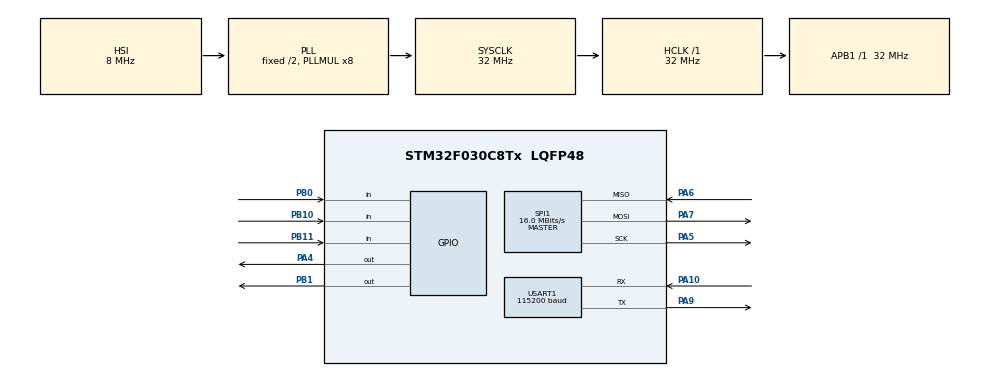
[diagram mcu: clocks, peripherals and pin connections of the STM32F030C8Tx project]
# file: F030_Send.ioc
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Mcu.Family=STM32F0
Mcu.Name=STM32F030C8Tx
Mcu.Package=LQFP48
NVIC.USART1_IRQn=true\:2\:0\:true\:false\:true\:true
PA10.Mode=Asynchronous
PA10.Signal=USART1_RX
PA13.Mode=Serial_Wire
PA13.Signal=SYS_SWDIO
PA14.Mode=Serial_Wire
PA14.Signal=SYS_SWCLK
PA4.Signal=GPIO_Output
PA5.Mode=Full_Duplex_Master
PA5.Signal=SPI1_SCK
PA6.Mode=Full_Duplex_Master
PA6.Signal=SPI1_MISO
PA7.Mode=Full_Duplex_Master
PA7.Signal=SPI1_MOSI
PA9.Mode=Asynchronous
PA9.Signal=USART1_TX
PB0.Signal=GPIO_Input
PB1.Signal=GPIO_Output
PB10.Signal=GPIO_Input
PB11.Signal=GPIO_Input
PF0-OSC_IN.Mode=HSE-External-Oscillator
PF0-OSC_IN.Signal=RCC_OSC_IN
PF1-OSC_OUT.Mode=HSE-External-Oscillator
PF1-OSC_OUT.Signal=RCC_OSC_OUT
ProjectManager.HeapSize=0x200
ProjectManager.StackSize=0x400
ProjectManager.TargetToolchain=MDK-ARM V5
RCC.AHBFreq_Value=32000000
RCC.APB1Freq_Value=32000000
RCC.APB1TimFreq_Value=32000000
RCC.HCLKFreq_Value=32000000
RCC.PLLMUL=RCC_PLL_MUL8
RCC.SYSCLKFreq_VALUE=32000000
RCC.SYSCLKSource=RCC_SYSCLKSOURCE_PLLCLK
RTC.Alarm-Alarm\ A=RTC_ALARM_A
SPI1.CalculateBaudRate=16.0 MBits/s
SPI1.DataSize=SPI_DATASIZE_8BIT
SPI1.Direction=SPI_DIRECTION_2LINES
SPI1.Mode=SPI_MODE_MASTER
SPI1.NSSPMode=SPI_NSS_PULSE_DISABLE
SPI1.VirtualType=VM_MASTER
USART1.BaudRate=115200
USART1.VirtualMode-Asynchronous=VM_ASYNC
VP_RTC_VS_RTC_Activate.Mode=RTC_Enabled
VP_RTC_VS_RTC_Alarm_A_Intern.Mode=Alarm A
VP_RTC_VS_RTC_Calendar.Mode=RTC_Calendar
board=custom

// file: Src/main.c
/* USER CODE BEGIN Header */
/**
  ******************************************************************************
  * @file           : main.c
  * @brief          : Main program body
  ******************************************************************************
  ** This notice applies to any and all portions of this file
  * that are not between comment pairs USER CODE BEGIN and
  * USER CODE END. Other portions of this file, whether
  * inserted by the user or by software development tools
  * are owned by their respective copyright owners.
  *
  * COPYRIGHT(c) 2019 STMicroelectronics
  *
  * Redistribution and use in source and binary forms, with or without modification,
  * are permitted provided that the following conditions are met:
  *   1. Redistributions of source code must retain the above copyright notice,
  *      this list of conditions and the following disclaimer.
  *   2. Redistributions in binary form must reproduce the above copyright notice,
  *      this list of conditions and the following disclaimer in the documentation
  *      and/or other materials provided with the distribution.
  *   3. Neither the name of STMicroelectronics nor the names of its contributors
  *      may be used to endorse or promote products derived from this software
  *      without specific prior written permission.
  *
  * THIS SOFTWARE IS PROVIDED BY THE COPYRIGHT HOLDERS AND CONTRIBUTORS "AS IS"
  * AND ANY EXPRESS OR IMPLIED WARRANTIES, INCLUDING, BUT NOT LIMITED TO, THE
  * IMPLIED WARRANTIES OF MERCHANTABILITY AND FITNESS FOR A PARTICULAR PURPOSE ARE
  * DISCLAIMED. IN NO EVENT SHALL THE COPYRIGHT HOLDER OR CONTRIBUTORS BE LIABLE
  * FOR ANY DIRECT, INDIRECT, INCIDENTAL, SPECIAL, EXEMPLARY, OR CONSEQUENTIAL
  * DAMAGES (INCLUDING, BUT NOT LIMITED TO, PROCUREMENT OF SUBSTITUTE GOODS OR
  * SERVICES; LOSS OF USE, DATA, OR PROFITS; OR BUSINESS INTERRUPTION) HOWEVER
  * CAUSED AND ON ANY THEORY OF LIABILITY, WHETHER IN CONTRACT, STRICT LIABILITY,
  * OR TORT (INCLUDING NEGLIGENCE OR OTHERWISE) ARISING IN ANY WAY OUT OF THE USE
  * OF THIS SOFTWARE, EVEN IF ADVISED OF THE POSSIBILITY OF SUCH DAMAGE.
  *
  ******************************************************************************
  */
/* USER CODE END Header */

#include "main.h"
#include "stm32f0xx_hal.h"
#include "function.h"
#include "SX127x.h"
#include "string.h"
#include "stm32f0xx_it.h"

RTC_HandleTypeDef hrtc;

SPI_HandleTypeDef hspi1;

UART_HandleTypeDef huart1;
 int8_t  USART_RX_BUF[50]; //接收缓冲,最大USART_REC_LEN个字节.末字节为换行符
 int16_t USART_RX_STA;         		//接收状态标记
 int8_t aRxBuffer[1];//HAL库USART接收Buffer

void SystemClock_Config(void);
static void MX_GPIO_Init(void);
static void MX_RTC_Init(void);
static void MX_SPI1_Init(void);
static void MX_USART1_UART_Init(void);

int main(void)
{

  /* MCU Configuration--------------------------------------------------------*/

  /* Reset of all peripherals, Initializes the Flash interface and the Systick. */
  HAL_Init();

  /* Configure the system clock */
  SystemClock_Config();

  /* Initialize all configured peripherals */
  MX_GPIO_Init();
  MX_RTC_Init();
  MX_SPI1_Init();
  MX_USART1_UART_Init();
  /* USER CODE BEGIN 2 */
	DebugPrintf("Uart1 Init done!\r\n");
  /* USER CODE END 2 */

	unsigned char gSendBuffer[1],Irq_flag = 0;
	SX127x_RLEN = 0;
	gSendBuffer[0] = 0x01;
//	unsigned char gSendBuffer[50] = "hello world！";
//	unsigned char len1=strlen((char       *)gSendBuffer);
//	unsigned char gSendBuffer1[50] = "你好世界！";
//	unsigned char len2=strlen((char       *)gSendBuffer);

	SX127xReset();
	SX127xLORA_INT();
	SX127xWriteBuffer(0x0A,123);
	SX127xReadBuffer(0x0A);
	DebugPrintf("SX127xReadBuffer 0x0A = %d\r\n",SX127xReadBuffer(0x0A));
  while (1)
  {
		FUN_RF_SENDPACKET(gSendBuffer,1);//发射数据 -- 0x01
		Irq_flag=SX127xReadBuffer( REG_LR_IRQFLAGS );
		while((Irq_flag & 0x08) != 0x08)
		{
			HAL_Delay(10);
			Irq_flag=SX127xReadBuffer( REG_LR_IRQFLAGS );
		}
		DebugPrintf("发送数据成功：%s\r\n",gSendBuffer);
		DebugPrintf("Send datapacket %s done!\r\n",gSendBuffer);
		HAL_Delay(1000);

		gSendBuffer[0] = 0x02;

		FUN_RF_SENDPACKET(gSendBuffer,1);//发射数据 -- 0x02
		Irq_flag=SX127xReadBuffer( REG_LR_IRQFLAGS );

		while((Irq_flag&0x08) != 0x08)
		{
			HAL_Delay(10);
			Irq_flag=SX127xReadBuffer( REG_LR_IRQFLAGS );
		}
		DebugPrintf("发送数据成功：%s\r\n",gSendBuffer);
		DebugPrintf("Send datapacket %s done!\r\n",gSendBuffer);
		HAL_Delay(1000);

		gSendBuffer[0] = 0x01;

  }
  /* USER CODE END 3 */
}

void SystemClock_Config(void)
{
  RCC_OscInitTypeDef RCC_OscInitStruct = {0};
  RCC_ClkInitTypeDef RCC_ClkInitStruct = {0};
  RCC_PeriphCLKInitTypeDef PeriphClkInit = {0};

  /**Initializes the CPU, AHB and APB busses clocks
  */
  RCC_OscInitStruct.OscillatorType = RCC_OSCILLATORTYPE_HSI|RCC_OSCILLATORTYPE_LSI;
  RCC_OscInitStruct.HSIState = RCC_HSI_ON;
  RCC_OscInitStruct.HSICalibrationValue = 16;
  RCC_OscInitStruct.LSIState = RCC_LSI_ON;
  RCC_OscInitStruct.PLL.PLLState = RCC_PLL_ON;
  RCC_OscInitStruct.PLL.PLLSource = RCC_PLLSOURCE_HSI;
  RCC_OscInitStruct.PLL.PLLMUL = RCC_PLL_MUL8;
  RCC_OscInitStruct.PLL.PREDIV = RCC_PREDIV_DIV1;
  if (HAL_RCC_OscConfig(&RCC_OscInitStruct) != HAL_OK)
  {
    Error_Handler();
  }
  /**Initializes the CPU, AHB and APB busses clocks
  */
  RCC_ClkInitStruct.ClockType = RCC_CLOCKTYPE_HCLK|RCC_CLOCKTYPE_SYSCLK
                              |RCC_CLOCKTYPE_PCLK1;
  RCC_ClkInitStruct.SYSCLKSource = RCC_SYSCLKSOURCE_PLLCLK;
  RCC_ClkInitStruct.AHBCLKDivider = RCC_SYSCLK_DIV1;
  RCC_ClkInitStruct.APB1CLKDivider = RCC_HCLK_DIV1;

  if (HAL_RCC_ClockConfig(&RCC_ClkInitStruct, FLASH_LATENCY_1) != HAL_OK)
  {
    Error_Handler();
  }
  PeriphClkInit.PeriphClockSelection = RCC_PERIPHCLK_USART1|RCC_PERIPHCLK_RTC;
  PeriphClkInit.Usart1ClockSelection = RCC_USART1CLKSOURCE_PCLK1;
  PeriphClkInit.RTCClockSelection = RCC_RTCCLKSOURCE_LSI;
  if (HAL_RCCEx_PeriphCLKConfig(&PeriphClkInit) != HAL_OK)
  {
    Error_Handler();
  }

	  HAL_SYSTICK_Config(HAL_RCC_GetHCLKFreq()/1000);

    /**Configure the Systick
    */
  HAL_SYSTICK_CLKSourceConfig(SYSTICK_CLKSOURCE_HCLK);

  /* SysTick_IRQn interrupt configuration */
   HAL_NVIC_SetPriority(SysTick_IRQn, 0, 0);
}

static void MX_RTC_Init(void)
{

  RTC_TimeTypeDef sTime = {0};
  RTC_DateTypeDef sDate = {0};
  RTC_AlarmTypeDef sAlarm = {0};

  /**Initialize RTC Only
  */
  hrtc.Instance = RTC;
  hrtc.Init.HourFormat = RTC_HOURFORMAT_24;
  hrtc.Init.AsynchPrediv = 127;
  hrtc.Init.SynchPrediv = 255;
  hrtc.Init.OutPut = RTC_OUTPUT_DISABLE;
  hrtc.Init.OutPutPolarity = RTC_OUTPUT_POLARITY_HIGH;
  hrtc.Init.OutPutType = RTC_OUTPUT_TYPE_OPENDRAIN;
  if (HAL_RTC_Init(&hrtc) != HAL_OK)
  {
    Error_Handler();
  }

  /**Initialize RTC and set the Time and Date
  */
  sTime.Hours = 0x0;
  sTime.Minutes = 0x0;
  sTime.Seconds = 0x0;
  sTime.DayLightSaving = RTC_DAYLIGHTSAVING_NONE;
  sTime.StoreOperation = RTC_STOREOPERATION_RESET;
  if (HAL_RTC_SetTime(&hrtc, &sTime, RTC_FORMAT_BCD) != HAL_OK)
  {
    Error_Handler();
  }
  sDate.WeekDay = RTC_WEEKDAY_MONDAY;
  sDate.Month = RTC_MONTH_JANUARY;
  sDate.Date = 0x1;
  sDate.Year = 0x0;

  if (HAL_RTC_SetDate(&hrtc, &sDate, RTC_FORMAT_BCD) != HAL_OK)
  {
    Error_Handler();
  }
  /**Enable the Alarm A
  */
  sAlarm.AlarmTime.Hours = 0x0;
  sAlarm.AlarmTime.Minutes = 0x0;
  sAlarm.AlarmTime.Seconds = 0x0;
  sAlarm.AlarmTime.SubSeconds = 0x0;
  sAlarm.AlarmTime.DayLightSaving = RTC_DAYLIGHTSAVING_NONE;
  sAlarm.AlarmTime.StoreOperation = RTC_STOREOPERATION_RESET;
  sAlarm.AlarmMask = RTC_ALARMMASK_NONE;
  sAlarm.AlarmSubSecondMask = RTC_ALARMSUBSECONDMASK_ALL;
  sAlarm.AlarmDateWeekDaySel = RTC_ALARMDATEWEEKDAYSEL_DATE;
  sAlarm.AlarmDateWeekDay = 0x1;
  sAlarm.Alarm = RTC_ALARM_A;
  if (HAL_RTC_SetAlarm(&hrtc, &sAlarm, RTC_FORMAT_BCD) != HAL_OK)
  {
    Error_Handler();
  }

}

static void MX_SPI1_Init(void)
{

  /* SPI1 parameter configuration*/
  hspi1.Instance = SPI1;
  hspi1.Init.Mode = SPI_MODE_MASTER;
  hspi1.Init.Direction = SPI_DIRECTION_2LINES;
  hspi1.Init.DataSize = SPI_DATASIZE_8BIT;
  hspi1.Init.CLKPolarity = SPI_POLARITY_LOW;
  hspi1.Init.CLKPhase = SPI_PHASE_1EDGE;
  hspi1.Init.NSS = SPI_NSS_SOFT;
  hspi1.Init.BaudRatePrescaler = SPI_BAUDRATEPRESCALER_2;
  hspi1.Init.FirstBit = SPI_FIRSTBIT_MSB;
  hspi1.Init.TIMode = SPI_TIMODE_DISABLE;
  hspi1.Init.CRCCalculation = SPI_CRCCALCULATION_DISABLE;
  hspi1.Init.CRCPolynomial = 10;
  hspi1.Init.CRCLength = SPI_CRC_LENGTH_DATASIZE;
  hspi1.Init.NSSPMode = SPI_NSS_PULSE_DISABLE;
  if (HAL_SPI_Init(&hspi1) != HAL_OK)
  {
    Error_Handler();
  }

}

static void MX_USART1_UART_Init(void)
{

  huart1.Instance = USART1;
  huart1.Init.BaudRate = 115200;
  huart1.Init.WordLength = UART_WORDLENGTH_8B;
  huart1.Init.StopBits = UART_STOPBITS_1;
  huart1.Init.Parity = UART_PARITY_NONE;
  huart1.Init.Mode = UART_MODE_TX_RX;
  huart1.Init.HwFlowCtl = UART_HWCONTROL_NONE;
  huart1.Init.OverSampling = UART_OVERSAMPLING_16;
  huart1.Init.OneBitSampling = UART_ONE_BIT_SAMPLE_DISABLE;
  huart1.AdvancedInit.AdvFeatureInit = UART_ADVFEATURE_NO_INIT;
  if (HAL_UART_Init(&huart1) != HAL_OK)
  {
    Error_Handler();
  }
  HAL_UART_Receive_IT(&huart1, (uint8_t *)aRxBuffer, 1);
}

static void MX_GPIO_Init(void)
{
  GPIO_InitTypeDef GPIO_InitStruct = {0};

  /* GPIO Ports Clock Enable */
  __HAL_RCC_GPIOF_CLK_ENABLE();
  __HAL_RCC_GPIOA_CLK_ENABLE();
  __HAL_RCC_GPIOB_CLK_ENABLE();

  /*Configure GPIO pin Output Level */
  HAL_GPIO_WritePin(GPIOA, GPIO_PIN_4, GPIO_PIN_RESET);

  /*Configure GPIO pin Output Level */
  HAL_GPIO_WritePin(GPIOB, GPIO_PIN_1, GPIO_PIN_RESET);

  /*Configure GPIO pin : PA4 */
  GPIO_InitStruct.Pin = GPIO_PIN_4;
  GPIO_InitStruct.Mode = GPIO_MODE_OUTPUT_PP;
  GPIO_InitStruct.Pull = GPIO_NOPULL;
  GPIO_InitStruct.Speed = GPIO_SPEED_FREQ_LOW;
  HAL_GPIO_Init(GPIOA, &GPIO_InitStruct);

  /*Configure GPIO pins : PB0 PB10 PB11 */
  GPIO_InitStruct.Pin = GPIO_PIN_0|GPIO_PIN_10|GPIO_PIN_11|GPIO_PIN_3;
  GPIO_InitStruct.Mode = GPIO_MODE_INPUT;
  GPIO_InitStruct.Pull = GPIO_NOPULL;
  HAL_GPIO_Init(GPIOB, &GPIO_InitStruct);

  /*Configure GPIO pin : PB1 */
  GPIO_InitStruct.Pin = GPIO_PIN_1;
  GPIO_InitStruct.Mode = GPIO_MODE_OUTPUT_PP;
  GPIO_InitStruct.Pull = GPIO_NOPULL;
  GPIO_InitStruct.Speed = GPIO_SPEED_FREQ_LOW;
  HAL_GPIO_Init(GPIOB, &GPIO_InitStruct);

}

void Error_Handler(void)
{
}

/************************ (C) COPYRIGHT STMicroelectronics *****END OF FILE****/
